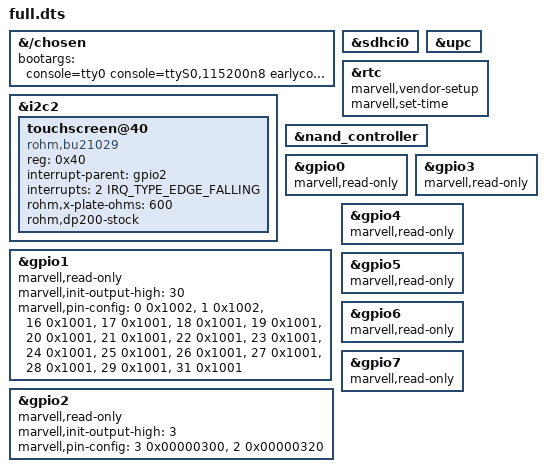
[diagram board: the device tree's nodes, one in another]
// SPDX-License-Identifier: GPL-2.0
/*
 * full variant: SD, UPC, GPIO (read-only), I2C bus 2, the RTC (read-only)
 * and the NAND (read-only) enabled; consoleblank=0 for the panel console.
 */
#include "88pa6170-dp200.dts"

&{/chosen} {
	bootargs = "console=tty0 console=ttyS0,115200n8 earlycon=uart8250,mmio32,0xf8060000 rdinit=/init panic=10 consoleblank=0";
};

&sdhci0 { status = "okay"; };
&upc { status = "okay"; };
/*
 * Touch controller: ROHM BU21029GUL at 0x40, interrupt GPIO 66 (bank 2
 * line 2, falling edge as the stock pin configuration 0x320), reset/enable
 * GPIO 67 held high by gpio2's board setup (so no reset-gpios here: the bank
 * is read-only). rohm,dp200-stock: the vendor rohm_ts register init, and
 * ABS_MT_POSITION_X/Y with the stock raw ranges (patch 0008).
 */
&i2c2 {
	status = "okay";

	touchscreen@40 {
		compatible = "rohm,bu21029";
		reg = <0x40>;
		interrupt-parent = <&gpio2>;
		interrupts = <2 IRQ_TYPE_EDGE_FALLING>;
		rohm,x-plate-ohms = <600>;
		rohm,dp200-stock;
	};
};
/*
 * RTC: the vendor setup and set_time, both user-approved 2026-10-30.
 */
&rtc {
	status = "okay";
	marvell,vendor-setup;
	marvell,set-time;	/* user-approved 2026-10-30: hwclock -w */
};
&nand_controller { status = "okay"; };
&gpio0 { status = "okay"; marvell,read-only; };
/*
 * Bank 1 board setup, user-approved values only, so that a boot straight
 * from U-Boot needs neither --pinmux-sd nor the eth loader's script:
 * SD pins 0/1 = 0x1002 (the two selects U-Boot leaves different from
 * stock), the Ethernet RGMII + MDC/MDIO pads 16-29 and 31 = 0x1001
 * (eth-pinmux rev 2), and GPIO 62 (line 30, the PHY reset) driven high.
 */
&gpio1 {
	status = "okay";
	marvell,read-only;
	marvell,init-output-high = <30>;
	marvell,pin-config = <0 0x1002>, <1 0x1002>,
		<16 0x1001>, <17 0x1001>, <18 0x1001>, <19 0x1001>,
		<20 0x1001>, <21 0x1001>, <22 0x1001>, <23 0x1001>,
		<24 0x1001>, <25 0x1001>, <26 0x1001>, <27 0x1001>,
		<28 0x1001>, <29 0x1001>, <31 0x1001>;
};
/*
 * Touch controller (BU21029, I2C bus 2 at 0x40): GPIO 67 (bank 2 line 3) is
 * its reset/enable, driven high as stock (gr_def_mpp_list); GPIO 66 (line 2)
 * is its interrupt input. Pin selects as stock (0x300, 0x320). User-approved
 * (touch-pins test). The bank stays read-only at runtime.
 */
&gpio2 {
	status = "okay";
	marvell,read-only;
	marvell,init-output-high = <3>;
	marvell,pin-config = <3 0x00000300>, <2 0x00000320>;
};
&gpio3 { status = "okay"; marvell,read-only; };
&gpio4 { status = "okay"; marvell,read-only; };
&gpio5 { status = "okay"; marvell,read-only; };
&gpio6 { status = "okay"; marvell,read-only; };
&gpio7 { status = "okay"; marvell,read-only; };
